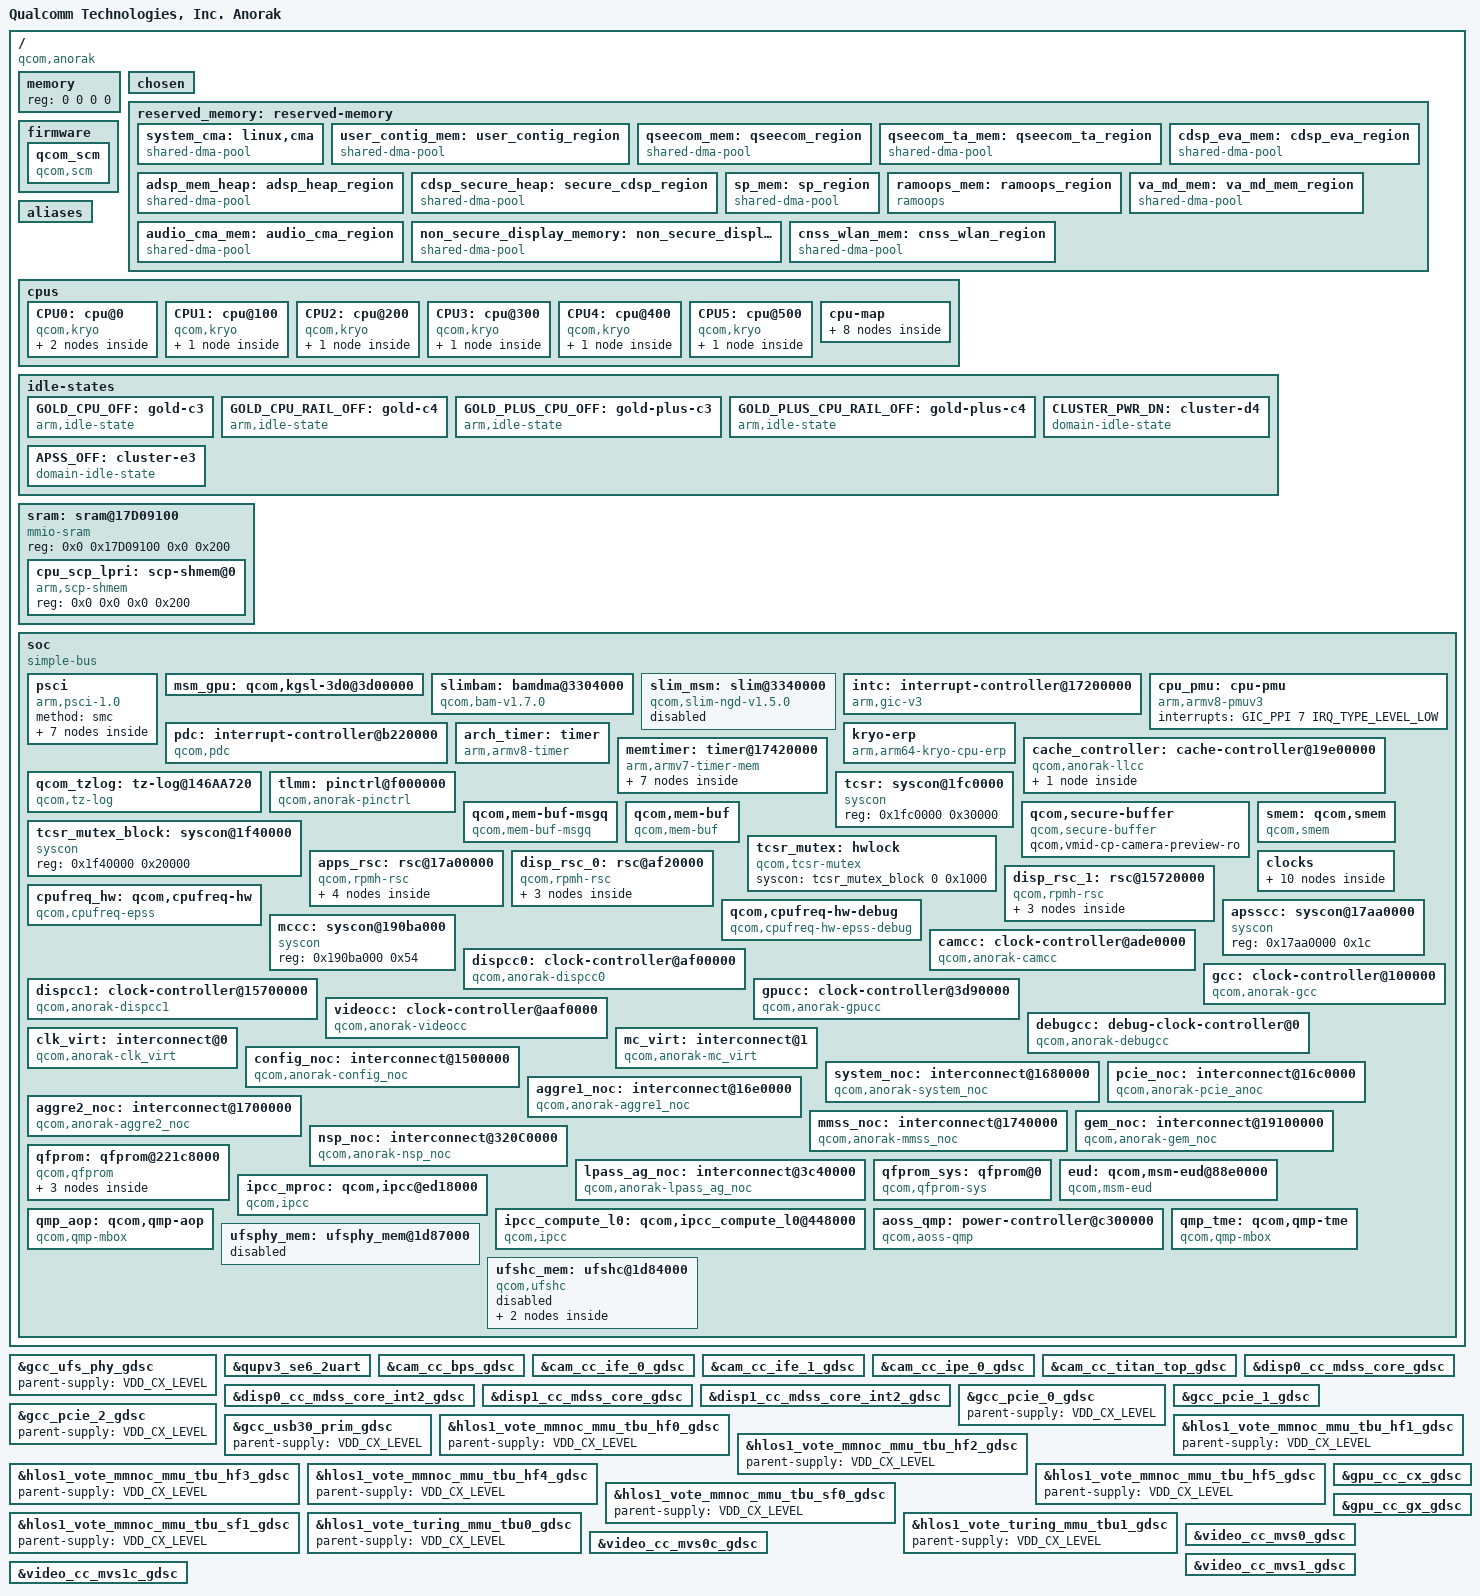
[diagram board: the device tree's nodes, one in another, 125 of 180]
#include <dt-bindings/clock/qcom,rpmh.h>
#include <dt-bindings/clock/qcom,camcc-anorak.h>
#include <dt-bindings/clock/qcom,dispcc-anorak.h>
#include <dt-bindings/clock/qcom,gcc-anorak.h>
#include <dt-bindings/clock/qcom,gpucc-anorak.h>
#include <dt-bindings/clock/qcom,videocc-anorak.h>
#include <dt-bindings/interrupt-controller/arm-gic.h>
#include <dt-bindings/soc/qcom,rpmh-rsc.h>
#include <dt-bindings/regulator/qcom,rpmh-regulator-levels.h>
#include <dt-bindings/interconnect/qcom,icc.h>
#include <dt-bindings/interconnect/qcom,anorak.h>
#include <dt-bindings/power/qcom-aoss-qmp.h>
#include <dt-bindings/clock/qcom,aop-qmp.h>
#include <dt-bindings/soc/qcom,ipcc.h>
#include <dt-bindings/gpio/gpio.h>

/ {
	model = "Qualcomm Technologies, Inc. Anorak";
	compatible = "qcom,anorak";
	qcom,msm-id = <549 0x10000>;
	interrupt-parent = <&intc>;

	#address-cells = <2>;
	#size-cells = <2>;
	memory { device_type = "memory"; reg = <0 0 0 0>; };

	chosen: chosen { bootargs = "console=ttyMSM0,115200n8 loglevel=6 log_buf_len=256K kernel.panic_on_rcu_stall=1 loop.max_part=7 pcie_ports=compat service_locator.enable=1 msm_rtb.filter=0x237 allow_mismatched_32bit_el0 kasan=off rcupdate.rcu_expedited=1 ftrace_dump_on_oops kpti=off rcu_nocbs=0-5 swiotlb=noforce cgroup.memory=nokmem,nosocket can.stats_timer=0 disable_dma32=on cpufreq.default_governor=performance ufs_qcom.crash_on_ber=n"; };

	reserved_memory: reserved-memory { };

	firmware: firmware { };

	aliases: aliases {
			serial0 = &qupv3_se6_2uart;
			ufshc1 = &ufshc_mem; /* Embedded UFS Slot */
			hsuart0 = &qupv3_se5_4uart;
	};

	cpus {
		#address-cells = <2>;
		#size-cells = <0>;

		CPU0: cpu@0 {
			device_type = "cpu";
			compatible = "qcom,kryo";
			reg = <0x0 0x0>;
			cpu-idle-states = <&GOLD_CPU_OFF &GOLD_CPU_RAIL_OFF>;
			power-domains = <&CPU_PD0>;
			power-domain-names = "psci";
			enable-method = "psci";
			next-level-cache = <&L2_0>;
			capacity-dmips-mhz = <1024>;
			dynamic-power-coefficient = <100>;
			#cooling-cells = <2>;
			qcom,freq-domain = <&cpufreq_hw 0>;
			L2_0: l2-cache {
			      compatible = "arm,arch-cache";
			      cache-level = <2>;
			      next-level-cache = <&L3_0>;

				L3_0: l3-cache {
					compatible = "arm,arch-cache";
					cache-level = <3>;
				};
			};
		};

		CPU1: cpu@100 {
			device_type = "cpu";
			compatible = "qcom,kryo";
			reg = <0x0 0x100>;
			enable-method = "psci";
			cpu-idle-states = <&GOLD_CPU_OFF &GOLD_CPU_RAIL_OFF>;
			power-domains = <&CPU_PD1>;
			power-domain-names = "psci";
			next-level-cache = <&L2_1>;
			capacity-dmips-mhz = <1024>;
			dynamic-power-coefficient = <100>;
			#cooling-cells = <2>;
			qcom,freq-domain = <&cpufreq_hw 0>;
			L2_1: l2-cache {
			      compatible = "arm,arch-cache";
			      cache-level = <2>;
			      next-level-cache = <&L3_0>;
			};

		};

		CPU2: cpu@200 {
			device_type = "cpu";
			compatible = "qcom,kryo";
			reg = <0x0 0x200>;
			enable-method = "psci";
			cpu-idle-states = <&GOLD_PLUS_CPU_OFF &GOLD_PLUS_CPU_RAIL_OFF>;
			power-domains = <&CPU_PD2>;
			power-domain-names = "psci";
			next-level-cache = <&L2_2>;
			capacity-dmips-mhz = <1075>;
			dynamic-power-coefficient = <109>;
			#cooling-cells = <2>;
			qcom,freq-domain = <&cpufreq_hw 1>;
			L2_2: l2-cache {
			      compatible = "arm,arch-cache";
			      cache-level = <2>;
			      next-level-cache = <&L3_0>;
			};
		};

		CPU3: cpu@300 {
			device_type = "cpu";
			compatible = "qcom,kryo";
			reg = <0x0 0x300>;
			enable-method = "psci";
			cpu-idle-states = <&GOLD_PLUS_CPU_OFF &GOLD_PLUS_CPU_RAIL_OFF>;
			power-domains = <&CPU_PD3>;
			power-domain-names = "psci";
			next-level-cache = <&L2_3>;
			capacity-dmips-mhz = <1075>;
			dynamic-power-coefficient = <109>;
			#cooling-cells = <2>;
			qcom,freq-domain = <&cpufreq_hw 1>;
			L2_3: l2-cache {
			      compatible = "arm,arch-cache";
			      cache-level = <2>;
			      next-level-cache = <&L3_0>;
			};

		};

		CPU4: cpu@400 {
			device_type = "cpu";
			compatible = "qcom,kryo";
			reg = <0x0 0x400>;
			enable-method = "psci";
			cpu-idle-states = <&GOLD_PLUS_CPU_OFF &GOLD_PLUS_CPU_RAIL_OFF>;
			power-domains = <&CPU_PD4>;
			power-domain-names = "psci";
			next-level-cache = <&L2_4>;
			capacity-dmips-mhz = <1075>;
			dynamic-power-coefficient = <109>;
			#cooling-cells = <2>;
			qcom,freq-domain = <&cpufreq_hw 1>;
			L2_4: l2-cache {
				compatible = "arm,arch-cache";
				cache-level = <2>;
				next-level-cache = <&L3_0>;
			};
		};

		CPU5: cpu@500 {
			device_type = "cpu";
			compatible = "qcom,kryo";
			reg = <0x0 0x500>;
			enable-method = "psci";
			cpu-idle-states = <&GOLD_PLUS_CPU_OFF &GOLD_PLUS_CPU_RAIL_OFF>;
			power-domains = <&CPU_PD5>;
			power-domain-names = "psci";
			next-level-cache = <&L2_5>;
			capacity-dmips-mhz = <1075>;
			dynamic-power-coefficient = <109>;
			#cooling-cells = <2>;
			qcom,freq-domain = <&cpufreq_hw 1>;
			L2_5: l2-cache {
				compatible = "arm,arch-cache";
				cache-level = <2>;
				next-level-cache = <&L3_0>;
			};
		};

		cpu-map {
			cluster0 {
				core0 {
					cpu = <&CPU0>;
				};

				core1 {
					cpu = <&CPU1>;
				};
			};

			cluster1 {
				core0 {
					cpu = <&CPU2>;
				};

				core1 {
					cpu = <&CPU3>;
				};

				core2 {
					cpu = <&CPU4>;
				};

				core3 {
					cpu = <&CPU5>;
				};
			};
		};
	};

	idle-states {
		GOLD_CPU_OFF: gold-c3 {  /* C3 */
			compatible = "arm,idle-state";
			idle-state-name = "pc";
			entry-latency-us = <400>;
			exit-latency-us = <1400>;
			min-residency-us = <2207>;
			arm,psci-suspend-param = <0x40000003>;
			local-timer-stop;
		};

		GOLD_CPU_RAIL_OFF: gold-c4 {  /* C4 */
			compatible = "arm,idle-state";
			idle-state-name = "rail-pc";
			entry-latency-us = <600>;
			exit-latency-us = <1300>;
			min-residency-us = <8136>;
			arm,psci-suspend-param = <0x40000004>;
			local-timer-stop;
		};

		GOLD_PLUS_CPU_OFF: gold-plus-c3 {  /* C3 */
			compatible = "arm,idle-state";
			idle-state-name = "pc";
			entry-latency-us = <300>;
			exit-latency-us = <1450>;
			min-residency-us = <3230>;
			arm,psci-suspend-param = <0x40000003>;
			local-timer-stop;
		};

		GOLD_PLUS_CPU_RAIL_OFF: gold-plus-c4 {  /* C4 */
			compatible = "arm,idle-state";
			idle-state-name = "rail-pc";
			entry-latency-us = <500>;
			exit-latency-us = <1350>;
			min-residency-us = <7480>;
			arm,psci-suspend-param = <0x40000004>;
			local-timer-stop;
		};

		CLUSTER_PWR_DN: cluster-d4 { /* D4 */
			compatible = "domain-idle-state";
			idle-state-name = "l3-off";
			entry-latency-us = <1050>;
			exit-latency-us = <2500>;
			min-residency-us = <9309>;
			arm,psci-suspend-param = <0x41000044>;
		};

		APSS_OFF: cluster-e3 { /* E3 */
			compatible = "domain-idle-state";
			idle-state-name = "llcc-off";
			entry-latency-us = <2700>;
			exit-latency-us = <3500>;
			min-residency-us = <13959>;
			arm,psci-suspend-param = <0x4100c344>;
		};
	};

	sram: sram@17D09100 {
		#address-cells = <2>;
		#size-cells = <2>;
		compatible = "mmio-sram";
		reg = <0x0 0x17D09100 0x0 0x200>;
		ranges = <0x0 0x0 0x0 0x17D09100 0x0 0x200>;

		cpu_scp_lpri: scp-shmem@0 {
			compatible = "arm,scp-shmem";
			reg = <0x0 0x0 0x0 0x200>;
		};
	};

	soc: soc { };
};

#include "anorak-reserved-memory.dtsi"

&reserved_memory {
	#address-cells = <2>;
	#size-cells = <2>;
	ranges;

	/* global autoconfigured region for contiguous allocations */
	system_cma: linux,cma {
		compatible = "shared-dma-pool";
		alloc-ranges = <0x0 0x00000000 0x0 0xffffffff>;
		reusable;
		alignment = <0x0 0x400000>;
		size = <0x0 0x2000000>;
		linux,cma-default;
	};

	user_contig_mem: user_contig_region {
		compatible = "shared-dma-pool";
		alloc-ranges = <0x0 0x00000000 0x0 0xffffffff>;
		reusable;
		alignment = <0x0 0x400000>;
		size = <0x0 0x1000000>;
	};

	qseecom_mem: qseecom_region {
		compatible = "shared-dma-pool";
		alloc-ranges = <0x0 0x00000000 0x0 0xffffffff>;
		reusable;
		alignment = <0x0 0x400000>;
		size = <0x0 0x1400000>;
	};

	qseecom_ta_mem: qseecom_ta_region {
		compatible = "shared-dma-pool";
		alloc-ranges = <0x0 0x00000000 0x0 0xffffffff>;
		reusable;
		alignment = <0x0 0x400000>;
		size = <0x0 0x1000000>;
	};

	cdsp_eva_mem: cdsp_eva_region {
		compatible = "shared-dma-pool";
		alloc-ranges = <0x0 0x00000000 0x0 0xffffffff>;
		reusable;
		alignment = <0x0 0x400000>;
		size = <0x0 0x400000>;
	};

	adsp_mem_heap: adsp_heap_region {
		compatible = "shared-dma-pool";
		alloc-ranges = <0x0 0x00000000 0x0 0xffffffff>;
		reusable;
		alignment = <0x0 0x400000>;
		size = <0x0 0xC00000>;
	};

	cdsp_secure_heap: secure_cdsp_region { /* Secure DSP */
		compatible = "shared-dma-pool";
		alloc-ranges = <0x0 0x00000000 0x0 0xffffffff>;
		reusable;
		alignment = <0x0 0x400000>;
		size = <0x0 0x2800000>;
	};

	sp_mem: sp_region {  /* SPSS-HLOS ION shared mem */
		compatible = "shared-dma-pool";
		alloc-ranges = <0x0 0x00000000 0x0 0xffffffff>;
		reusable;
		alignment = <0x0 0x400000>;
		size = <0x0 0x1000000>;
	};

	ramoops_mem: ramoops_region {
		compatible = "ramoops";
		alloc-ranges = <0x0 0x00000000 0xffffffff 0xffffffff>;
		size = <0x0 0x200000>;
		pmsg-size = <0x200000>;
		mem-type = <2>;
	};

	va_md_mem: va_md_mem_region {
		compatible = "shared-dma-pool";
		alloc-ranges = <0x1 0x00000000 0xfffffffe 0xffffffff>;
		reusable;
		size = <0 0x1000000>;
	};

	audio_cma_mem: audio_cma_region {
	compatible = "shared-dma-pool";
	alloc-ranges = <0x0 0x00000000 0x0 0xffffffff>;
	reusable;
	alignment = <0x0 0x400000>;
	size = <0x0 0x1000000>;
	};

	non_secure_display_memory: non_secure_display_region {
		compatible = "shared-dma-pool";
		reusable;
		alloc-ranges = <0x0 0x00000000 0x0 0xffffffff>;
		size = <0x0 0xa400000>;
		alignment = <0x0 0x400000>;
	};

	cnss_wlan_mem: cnss_wlan_region {
		compatible = "shared-dma-pool";
		alloc-ranges = <0x0 0x00000000 0x0 0xffffffff>;
		reusable;
		alignment = <0x0 0x400000>;
		size = <0x0 0x2000000>;
	};
};

&firmware {
	qcom_scm {
		compatible = "qcom,scm";
		qcom,dload-mode = <&tcsr 0x13000>;
		qcom,no-multi-smc-support;
	};
};

&soc {
	#address-cells = <1>;
	#size-cells = <1>;
	ranges = <0 0 0 0xffffffff>;
	compatible = "simple-bus";

	psci {
		compatible = "arm,psci-1.0";
		method = "smc";

		CPU_PD0: cpu-pd0 {
			#power-domain-cells = <0>;
			power-domains = <&CLUSTER_PD>;
		};

		CPU_PD1: cpu-pd1 {
			#power-domain-cells = <0>;
			power-domains = <&CLUSTER_PD>;
		};

		CPU_PD2: cpu-pd2 {
			#power-domain-cells = <0>;
			power-domains = <&CLUSTER_PD>;
		};

		CPU_PD3: cpu-pd3 {
			#power-domain-cells = <0>;
			power-domains = <&CLUSTER_PD>;
		};

		CPU_PD4: cpu-pd4 {
			#power-domain-cells = <0>;
			power-domains = <&CLUSTER_PD>;
		};

		CPU_PD5: cpu-pd5 {
			#power-domain-cells = <0>;
			power-domains = <&CLUSTER_PD>;
		};

		CLUSTER_PD: cluster-pd {
			#power-domain-cells = <0>;
			domain-idle-states = <&CLUSTER_PWR_DN &APSS_OFF>;
		};
	};

	msm_gpu: qcom,kgsl-3d0@3d00000 { };

	slimbam: bamdma@3304000 {
		compatible = "qcom,bam-v1.7.0";
		qcom,controlled-remotely;
		reg = <0x3304000 0x20000>, <0x326b000 0x1000>;
		reg-names = "bam", "bam_remote_mem";
		num-channels  = <31>;
		interrupts = <0 164 IRQ_TYPE_LEVEL_HIGH>;
		#dma-cells = <1>;
		qcom,ee = <1>;
		qcom,num-ees = <2>;
	};

	slim_msm: slim@3340000 {
		compatible = "qcom,slim-ngd-v1.5.0";
		reg = <0x3340000 0x2C000>, <0x326a000 0x1000>;
		reg-names = "ctrl", "slimbus_remote_mem";
		interrupts = <0 163 IRQ_TYPE_LEVEL_HIGH>;
		dmas = <&slimbam 3>, <&slimbam 4>;
		dma-names = "rx", "tx";
		#address-cells = <1>;
		#size-cells = <0>;
		status = "disabled";
	};

	intc: interrupt-controller@17200000 {
		compatible = "arm,gic-v3";
		#interrupt-cells = <3>;
		interrupt-controller;
		#redistributor-regions = <1>;
		redistributor-stride = <0x0 0x20000>;
		reg = <0x17200000 0x10000>,	/* GICD */
		      <0x17260000 0x100000>;	/* GICR * 8 */
		interrupts = <GIC_PPI 9 IRQ_TYPE_LEVEL_LOW>;
	};

	cpu_pmu: cpu-pmu {
		compatible = "arm,armv8-pmuv3";
		interrupts = <GIC_PPI 7 IRQ_TYPE_LEVEL_LOW>;
	};

	pdc: interrupt-controller@b220000 {
		compatible = "qcom,pdc";
		reg = <0xb220000 0x30000>, <0x174000f0 0x64>;
		reg-names = "pdc-interrupt-base", "apss-shared-spi-cfg";
		qcom,pdc-ranges = <0 480 94>, <94 609 31>, <125 63 1>,
					<126 716 12>;
		#interrupt-cells = <2>;
		interrupt-parent = <&intc>;
		interrupt-controller;
	};


	arch_timer: timer {
		compatible = "arm,armv8-timer";
		interrupts = <GIC_PPI 13 (GIC_CPU_MASK_SIMPLE(8) | IRQ_TYPE_LEVEL_LOW)>,
			     <GIC_PPI 14 (GIC_CPU_MASK_SIMPLE(8) | IRQ_TYPE_LEVEL_LOW)>,
			     <GIC_PPI 11 (GIC_CPU_MASK_SIMPLE(8) | IRQ_TYPE_LEVEL_LOW)>,
			     <GIC_PPI 12 (GIC_CPU_MASK_SIMPLE(8) | IRQ_TYPE_LEVEL_LOW)>;
		clock-frequency = <19200000>;
	};

	kryo-erp {
		compatible = "arm,arm64-kryo-cpu-erp";
		interrupts = <GIC_PPI 0 IRQ_TYPE_LEVEL_HIGH>,
				<GIC_SPI 35 IRQ_TYPE_LEVEL_HIGH>;
		interrupt-names = "l1-l2-faultirq", "l3-scu-faultirq";
	};

	memtimer: timer@17420000 {
		#address-cells = <1>;
		#size-cells = <1>;
		ranges;
		compatible = "arm,armv7-timer-mem";
		reg = <0x17420000 0x1000>;
		clock-frequency = <19200000>;

		frame@17421000 {
			frame-number = <0>;
			interrupts = <GIC_SPI 8 IRQ_TYPE_LEVEL_HIGH>,
				     <GIC_SPI 6 IRQ_TYPE_LEVEL_HIGH>;
			reg = <0x17421000 0x1000>,
			      <0x17422000 0x1000>;
		};

		frame@17423000 {
			frame-number = <1>;
			interrupts = <GIC_SPI 9 IRQ_TYPE_LEVEL_HIGH>;
			reg = <0x17423000 0x1000>;
			status = "disabled";
		};

		frame@17425000 {
			frame-number = <2>;
			interrupts = <GIC_SPI 10 IRQ_TYPE_LEVEL_HIGH>;
			reg = <0x17425000 0x1000>;
			status = "disabled";
		};

		frame@17427000 {
			frame-number = <3>;
			interrupts = <GIC_SPI 11 IRQ_TYPE_LEVEL_HIGH>;
			reg = <0x17427000 0x1000>;
			status = "disabled";
		};

		frame@17429000 {
			frame-number = <4>;
			interrupts = <GIC_SPI 12 IRQ_TYPE_LEVEL_HIGH>;
			reg = <0x17429000 0x1000>;
			status = "disabled";
		};

		frame@1742b000 {
			frame-number = <5>;
			interrupts = <GIC_SPI 13 IRQ_TYPE_LEVEL_HIGH>;
			reg = <0x1742b000 0x1000>;
			status = "disabled";
		};

		frame@1742d000 {
			frame-number = <6>;
			interrupts = <GIC_SPI 14 IRQ_TYPE_LEVEL_HIGH>;
			reg = <0x1742d000 0x1000>;
			status = "disabled";
		};
	};

	cache_controller: cache-controller@19e00000 {
		compatible = "qcom,anorak-llcc", "qcom,llcc-v41";
		reg = <0x19e00000 0x800000>, <0x1a600000 0x200000>;
		reg-names = "llcc_base", "llcc_broadcast_base";
		interrupts = <GIC_SPI 266 IRQ_TYPE_LEVEL_HIGH>;
		cap-based-alloc-and-pwr-collapse;

		llcc-perfmon {
			compatible = "qcom,llcc-perfmon";
			clocks = <&aoss_qmp QDSS_CLK>;
			clock-names = "qdss_clk";
		};
	};

	qcom_tzlog: tz-log@146AA720 {
		compatible = "qcom,tz-log";
		reg = <0x146AA720 0x3000>;
		qcom,hyplog-enabled;
		hyplog-address-offset = <0x410>;
		hyplog-size-offset = <0x414>;
		tmecrashdump-address-offset = <0x81CA0000>;
	};

	tlmm: pinctrl@f000000 {
		compatible = "qcom,anorak-pinctrl";
		reg = <0xf000000 0x1000000>;
		interrupts = <GIC_SPI 208 IRQ_TYPE_LEVEL_HIGH>;
		gpio-controller;
		#gpio-cells = <2>;
		interrupt-controller;
		#interrupt-cells = <2>;
	};

	tcsr: syscon@1fc0000 {
		compatible = "syscon";
		reg = <0x1fc0000 0x30000>;
	};

	qcom,mem-buf-msgq {
		compatible = "qcom,mem-buf-msgq";
	};

	qcom,mem-buf {
		compatible = "qcom,mem-buf";
		qcom,mem-buf-capabilities = "supplier";
		qcom,vmid = <3>;
	};

	qcom,secure-buffer {
		compatible = "qcom,secure-buffer";
		qcom,vmid-cp-camera-preview-ro;
	};

	tcsr_mutex_block: syscon@1f40000 {
		compatible = "syscon";
		reg = <0x1f40000 0x20000>;
	};

	tcsr_mutex: hwlock {
		compatible = "qcom,tcsr-mutex";
		syscon = <&tcsr_mutex_block 0 0x1000>;
		#hwlock-cells = <1>;
	};

	smem: qcom,smem {
		compatible = "qcom,smem";
		memory-region = <&smem_mem>;
		hwlocks = <&tcsr_mutex 3>;
	};

	apps_rsc: rsc@17a00000 {
		label = "apps_rsc";
		compatible = "qcom,rpmh-rsc";
		reg = <0x17a00000 0x10000>,
		      <0x17a10000 0x10000>,
		      <0x17a20000 0x10000>;
		reg-names = "drv-0", "drv-1", "drv-2";
		qcom,drv-count = <3>;
		interrupts = <GIC_SPI 3 IRQ_TYPE_LEVEL_HIGH>,
			     <GIC_SPI 4 IRQ_TYPE_LEVEL_HIGH>,
			     <GIC_SPI 5 IRQ_TYPE_LEVEL_HIGH>;
		power-domains = <&CLUSTER_PD>;

		apps_rsc_drv2: drv@2 {
			qcom,drv-id = <2>;
			qcom,tcs-offset = <0xd00>;
			channel@0 {
				qcom,tcs-config = <ACTIVE_TCS    3>,
						  <SLEEP_TCS     2>,
						  <WAKE_TCS      2>,
						  <FAST_PATH_TCS 1>,
						  <CONTROL_TCS   0>;
			};

			rpmhcc: qcom,rpmhclk {
				compatible = "qcom,anorak-rpmh-clk";
				#clock-cells = <1>;
			};

			apps_bcm_voter: bcm_voter {
				compatible = "qcom,bcm-voter";
			};

		};
	};

	disp_rsc_0: rsc@af20000 {
		label = "disp_rsc_0";
		compatible = "qcom,rpmh-rsc";
		reg = <0xaf20000 0x10000>;
		reg-names = "drv-0";
		qcom,drv-count = <1>;
		interrupts = <GIC_SPI 129 IRQ_TYPE_LEVEL_HIGH>;

		disp_rsc_0_drv0: drv@0 {
			qcom,drv-id = <0>;
			qcom,tcs-offset = <0x1c00>;
			channel@0 {
				qcom,tcs-config = <ACTIVE_TCS    0>,
						  <SLEEP_TCS     1>,
						  <WAKE_TCS      1>,
						  <CONTROL_TCS   0>,
						  <FAST_PATH_TCS 0>;
			};

			disp0_bcm_voter: bcm_voter {
				compatible = "qcom,bcm-voter";
				qcom,tcs-wait = <QCOM_ICC_TAG_AMC>;
			};
		};
	};

	disp_rsc_1: rsc@15720000 {
		label = "disp_rsc_1";
		compatible = "qcom,rpmh-rsc";
		reg = <0x15720000 0x10000>;
		reg-names = "drv-0";
		qcom,drv-count = <1>;
		interrupts = <GIC_SPI 218 IRQ_TYPE_LEVEL_HIGH>;

		disp_rsc_1_drv0: drv@0 {
			qcom,drv-id = <0>;
			qcom,tcs-offset = <0x1c00>;
			channel@0 {
				qcom,tcs-config = <ACTIVE_TCS    0>,
						  <SLEEP_TCS     1>,
						  <WAKE_TCS      1>,
						  <CONTROL_TCS   0>,
						  <FAST_PATH_TCS 0>;
			};

			disp1_bcm_voter: bcm_voter {
				compatible = "qcom,bcm-voter";
				qcom,tcs-wait = <QCOM_ICC_TAG_AMC>;
			};
		};
	};

	clocks {
		xo_board: xo_board {
			compatible = "fixed-clock";
			clock-frequency = <76800000>;
			clock-output-names = "xo_board";
			#clock-cells = <0>;
		};

		sleep_clk: sleep_clk {
			compatible = "fixed-clock";
			clock-frequency = <32000>;
			clock-output-names = "sleep_clk";
			#clock-cells = <0>;
		};

		pcie_0_pipe_clk: pcie_0_pipe_clk {
			compatible = "fixed-clock";
			clock-frequency = <1000>;
			clock-output-names = "pcie_0_pipe_clk";
			#clock-cells = <0>;
		};

		pcie_1_pipe_clk: pcie_1_pipe_clk {
			compatible = "fixed-clock";
			clock-frequency = <1000>;
			clock-output-names = "pcie_1_pipe_clk";
			#clock-cells = <0>;
		};

		pcie_2_phy_aux_clk: pcie_2_phy_aux_clk {
			compatible = "fixed-clock";
			clock-frequency = <1000>;
			clock-output-names = "pcie_2_phy_aux_clk";
			#clock-cells = <0>;
		};

		pcie_2_pipe_clk: pcie_2_pipe_clk {
			compatible = "fixed-clock";
			clock-frequency = <1000>;
			clock-output-names = "pcie_2_pipe_clk";
			#clock-cells = <0>;
		};

		ufs_phy_rx_symbol_0_clk: ufs_phy_rx_symbol_0_clk {
			compatible = "fixed-clock";
			clock-frequency = <1000>;
			clock-output-names = "ufs_phy_rx_symbol_0_clk";
			#clock-cells = <0>;
		};

		ufs_phy_rx_symbol_1_clk: ufs_phy_rx_symbol_1_clk {
			compatible = "fixed-clock";
			clock-frequency = <1000>;
			clock-output-names = "ufs_phy_rx_symbol_1_clk";
			#clock-cells = <0>;
		};

		ufs_phy_tx_symbol_0_clk: ufs_phy_tx_symbol_0_clk {
			compatible = "fixed-clock";
			clock-frequency = <1000>;
			clock-output-names = "ufs_phy_tx_symbol_0_clk";
			#clock-cells = <0>;
		};

		usb3_phy_wrapper_gcc_usb30_pipe_clk: usb3_phy_wrapper_gcc_usb30_pipe_clk {
			compatible = "fixed-clock";
			clock-frequency = <1000>;
			clock-output-names = "usb3_phy_wrapper_gcc_usb30_pipe_clk";
			#clock-cells = <0>;
		};
	};

	cpufreq_hw: qcom,cpufreq-hw {
		compatible =  "qcom,cpufreq-epss";
		reg = <0x17d91000 0x1000>,
		      <0x17d92000 0x1000>;
		reg-names = "freq-domain0", "freq-domain1";
		clocks = <&rpmhcc RPMH_CXO_CLK>, <&gcc GCC_GPLL0>;
		clock-names = "xo", "alternate";
		interrupts = <GIC_SPI 30 IRQ_TYPE_LEVEL_HIGH>,
			     <GIC_SPI 31 IRQ_TYPE_LEVEL_HIGH>;
		interrupt-names = "dcvsh0_int", "dcvsh1_int";
		#freq-domain-cells = <1>;
	};

	qcom,cpufreq-hw-debug {
		compatible = "qcom,cpufreq-hw-epss-debug";
		qcom,freq-hw-domain = <&cpufreq_hw 0>, <&cpufreq_hw 1>;
	};

	apsscc: syscon@17aa0000 {
		compatible = "syscon";
		reg = <0x17aa0000 0x1c>;
	};

	mccc: syscon@190ba000 {
		compatible = "syscon";
		reg = <0x190ba000 0x54>;
	};

	camcc: clock-controller@ade0000 {
		compatible = "qcom,anorak-camcc", "syscon";
		reg = <0xade0000 0x20000>;
		reg-name = "cc_base";
		vdd_mm-supply = <&VDD_MM_LEVEL>;
		vdd_mxa-supply = <&VDD_MXA_LEVEL>;
		vdd_mxc-supply = <&VDD_MXC_LEVEL>;
		clocks = <&rpmhcc RPMH_CXO_CLK>,
			<&sleep_clk>,
			<&gcc GCC_CAMERA_AHB_CLK>;
		clock-names = "bi_tcxo",
			"sleep_clk","iface";
		clock-output-names = "camcc_clocks";
		#clock-cells = <1>;
		#reset-cells = <1>;
	};

	dispcc0: clock-controller@af00000 {
		compatible = "qcom,anorak-dispcc0", "syscon";
		reg = <0xaf00000 0x20000>;
		reg-name = "cc_base";
		vdd_mm-supply = <&VDD_MM_LEVEL>;
		vdd_mxa-supply = <&VDD_MXA_LEVEL>;
		clocks = <&rpmhcc RPMH_CXO_CLK>,
			 <&rpmhcc RPMH_CXO_CLK_A>,
			 <&sleep_clk>,
			 <&gcc GCC_DISP_AHB_CLK>;
		clock-names = "bi_tcxo", "bi_tcxo_ao", "sleep_clk", "iface";
		#clock-cells = <1>;
		#reset-cells = <1>;
	};

	dispcc1: clock-controller@15700000 {
		compatible = "qcom,anorak-dispcc1", "syscon";
		reg = <0x15700000 0x20000>;
		reg-name = "cc_base";
		vdd_mm-supply = <&VDD_MM_LEVEL>;
		vdd_mxa-supply = <&VDD_MXA_LEVEL>;
		clocks = <&rpmhcc RPMH_CXO_CLK>,
			 <&rpmhcc RPMH_CXO_CLK_A>,
			 <&sleep_clk>,
			 <&gcc GCC_DISP1_AHB_CLK>;
		clock-names = "bi_tcxo", "bi_tcxo_ao", "sleep_clk", "iface";
		#clock-cells = <1>;
		#reset-cells = <1>;
	};

	gcc: clock-controller@100000 {
		compatible = "qcom,anorak-gcc", "syscon";
		reg = <0x100000 0x1f4200>;
		reg-name = "cc_base";
		vdd_cx-supply = <&VDD_CX_LEVEL>;
		vdd_mxa-supply = <&VDD_MXA_LEVEL>;
		clocks = <&rpmhcc RPMH_CXO_CLK>, <&sleep_clk>,
			<&pcie_0_pipe_clk>, <&pcie_1_pipe_clk>,
			<&pcie_2_phy_aux_clk>, <&pcie_2_pipe_clk>,
			<&ufs_phy_rx_symbol_0_clk>, <&ufs_phy_rx_symbol_1_clk>,
			<&ufs_phy_tx_symbol_0_clk>, <&usb3_phy_wrapper_gcc_usb30_pipe_clk>;
		clock-names = "bi_tcxo", "sleep_clk",
			"pcie_0_pipe_clk", "pcie_1_pipe_clk",
			"pcie_2_phy_aux_clk", "pcie_2_pipe_clk",
			"ufs_phy_rx_symbol_0_clk", "ufs_phy_rx_symbol_1_clk",
			"ufs_phy_tx_symbol_0_clk", "usb3_phy_wrapper_gcc_usb30_pipe_clk";
		#clock-cells = <1>;
		#reset-cells = <1>;
	};

	gpucc: clock-controller@3d90000 {
		compatible = "qcom,anorak-gpucc", "syscon";
		reg = <0x3d90000 0xa000>;
		reg-name = "cc_base";
		vdd_cx-supply = <&VDD_CX_LEVEL>;
		vdd_mxa-supply = <&VDD_MXA_LEVEL>;
		vdd_mxc-supply = <&VDD_MXC_LEVEL>;
		clocks = <&rpmhcc RPMH_CXO_CLK>,
			<&gcc GCC_GPU_GPLL0_CLK_SRC>,
			<&gcc GCC_GPU_GPLL0_DIV_CLK_SRC>;
		clock-names = "bi_tcxo", "gpll0_out_main",
			"gpll0_out_main_div";
		#clock-cells = <1>;
		#reset-cells = <1>;
	};

	videocc: clock-controller@aaf0000 {
		compatible = "qcom,anorak-videocc", "syscon";
		reg = <0xaaf0000 0x10000>;
		reg-name = "cc_base";
		vdd_mm-supply = <&VDD_MM_LEVEL>;
		vdd_mxc-supply = <&VDD_MXC_LEVEL>;
		clocks = <&rpmhcc RPMH_CXO_CLK>,
			 <&sleep_clk>,
			 <&gcc GCC_VIDEO_AHB_CLK>;
		clock-names = "bi_tcxo",
			      "sleep_clk",
			      "iface";
		#clock-cells = <1>;
		#reset-cells = <1>;
	};

	debugcc: debug-clock-controller@0 {
		compatible = "qcom,anorak-debugcc";
		qcom,gcc = <&gcc>;
		qcom,videocc = <&videocc>;
		qcom,camcc = <&camcc>;
		qcom,gpucc = <&gpucc>;
		qcom,dispcc0 = <&dispcc0>;
		qcom,dispcc1 = <&dispcc1>;
		qcom,apsscc = <&apsscc>;
		qcom,mccc = <&mccc>;
		clocks = <&rpmhcc RPMH_CXO_CLK>,
			<&gcc 0>,<&camcc 0>,
			<&dispcc0 0>,<&dispcc1 0>,
			<&gpucc 0>,<&videocc 0>;
		clock-names = "xo_clk_src",
			      "gcc","camcc",
			      "dispcc0","dispcc1",
			      "gpucc","videocc";
		#clock-cells = <1>;
	};

	clk_virt: interconnect@0 {
		compatible = "qcom,anorak-clk_virt";
		#interconnect-cells = <1>;
		qcom,bcm-voter-names = "hlos";
		qcom,bcm-voters = <&apps_bcm_voter>;
	};

	mc_virt: interconnect@1 {
		compatible = "qcom,anorak-mc_virt";
		#interconnect-cells = <1>;
		qcom,bcm-voter-names = "hlos", "disp0", "disp1";
		qcom,bcm-voters = <&apps_bcm_voter>, <&disp0_bcm_voter>, <&disp1_bcm_voter>;
	};

	config_noc: interconnect@1500000 {
		reg = <0x1500000 0x13080>;
		compatible = "qcom,anorak-config_noc";
		#interconnect-cells = <1>;
		qcom,bcm-voter-names = "hlos";
		qcom,bcm-voters = <&apps_bcm_voter>;
	};

	system_noc: interconnect@1680000 {
		reg = <0x01680000 0x13080>;
		compatible = "qcom,anorak-system_noc";
		#interconnect-cells = <1>;
		qcom,bcm-voter-names = "hlos";
		qcom,bcm-voters = <&apps_bcm_voter>;
	};

	pcie_noc: interconnect@16c0000 {
		reg = <0x16C0000 0xC080>;
		compatible = "qcom,anorak-pcie_anoc";
		#interconnect-cells = <1>;
		qcom,bcm-voter-names = "hlos";
		qcom,bcm-voters = <&apps_bcm_voter>;
		clocks = <&gcc GCC_AGGRE_NOC_PCIE_AXI_CLK>,
			<&gcc GCC_CFG_NOC_PCIE_ANOC_AHB_CLK>,
			<&gcc GCC_AGGRE_NOC_PCIE_SF_AXI_CLK>;
	};

	aggre1_noc: interconnect@16e0000 {
		reg = <0x16E0000 0x9080>;
		compatible = "qcom,anorak-aggre1_noc";
		#interconnect-cells = <1>;
		qcom,bcm-voter-names = "hlos";
		qcom,bcm-voters = <&apps_bcm_voter>;
		clocks = <&gcc GCC_AGGRE_USB3_PRIM_AXI_CLK>;
	};

	aggre2_noc: interconnect@1700000 {
		reg = <0x1700000 0x15080>;
		compatible = "qcom,anorak-aggre2_noc";
		#interconnect-cells = <1>;
		qcom,bcm-voter-names = "hlos";
		qcom,bcm-voters = <&apps_bcm_voter>;
		clocks = <&rpmhcc RPMH_IPA_CLK>;
	};

	mmss_noc: interconnect@1740000 {
		reg = <0x01740000 0x1C100>;
		compatible = "qcom,anorak-mmss_noc";
		#interconnect-cells = <1>;
		qcom,bcm-voter-names = "hlos", "disp0", "disp1";
		qcom,bcm-voters = <&apps_bcm_voter>, <&disp0_bcm_voter>, <&disp1_bcm_voter>;
	};

	gem_noc: interconnect@19100000 {
		reg = <0x19100000 0xA9080>;
		compatible = "qcom,anorak-gem_noc";
		#interconnect-cells = <1>;
		qcom,bcm-voter-names = "hlos", "disp0", "disp1";
		qcom,bcm-voters = <&apps_bcm_voter>, <&disp0_bcm_voter>, <&disp1_bcm_voter>;
	};

	nsp_noc: interconnect@320C0000 {
		reg = <0x320C0000 0x10000>;
		compatible = "qcom,anorak-nsp_noc";
		#interconnect-cells = <1>;
		qcom,bcm-voter-names = "hlos";
		qcom,bcm-voters = <&apps_bcm_voter>;
	};

	lpass_ag_noc: interconnect@3c40000 {
		reg = <0x3c40000 0x17200>;
		compatible = "qcom,anorak-lpass_ag_noc";
		#interconnect-cells = <1>;
		qcom,bcm-voter-names = "hlos";
		qcom,bcm-voters = <&apps_bcm_voter>;
	};

	qfprom: qfprom@221c8000 {
		compatible = "qcom,qfprom";
		reg = <0x221c8000 0x1000>;
		#address-cells = <1>;
		#size-cells = <1>;
		read-only;
		ranges;

		feat_conf10: feat_conf10@128 {
			reg = <0x128 0x4>;
		};

		feat_conf11: feat_conf11@12c {
			reg = <0x12c 0x4>;
		};

		gpu_speed_bin: gpu_speed_bin@119 {
			reg = <0x119 0x2>;
			bits = <7 8>;
		};
	};

	qfprom_sys: qfprom@0 {
		compatible = "qcom,qfprom-sys";

		nvmem-cells = <&feat_conf10>,
				<&feat_conf11>,
				<&gpu_speed_bin>;
		nvmem-cell-names = "feat_conf10",
				"feat_conf11",
				"gpu_speed_bin";
	};

	eud: qcom,msm-eud@88e0000 {
		compatible = "qcom,msm-eud";
		interrupt-names = "eud_irq";
		interrupt-parent = <&pdc>;
		interrupts = <11 IRQ_TYPE_LEVEL_HIGH>;
		reg = <0x088e0000 0x2000>,
			<0x088e2000 0x1000>;
		reg-names = "eud_base", "eud_mode_mgr2";
		qcom,secure-eud-en;
		status = "ok";
	};

	ipcc_mproc: qcom,ipcc@ed18000 {
		compatible = "qcom,ipcc";
		reg = <0x408000 0x1000>;
		interrupts = <GIC_SPI 229 IRQ_TYPE_LEVEL_HIGH>;
		interrupt-controller;
		#interrupt-cells = <3>;
		#mbox-cells = <2>;
	};

	ipcc_compute_l0: qcom,ipcc_compute_l0@448000 {
		compatible = "qcom,ipcc";
		reg = <0x448000 0x1000>;
		interrupts = <GIC_SPI 230 IRQ_TYPE_LEVEL_HIGH>;
		interrupt-controller;
		#interrupt-cells = <3>;
		#mbox-cells = <2>;
	};

	aoss_qmp: power-controller@c300000 {
		compatible = "qcom,aoss-qmp";
		reg = <0xc300000 0x400>;
		interrupt-parent = <&ipcc_mproc>;
		interrupts = <IPCC_CLIENT_AOP
				IPCC_MPROC_SIGNAL_GLINK_QMP
				IRQ_TYPE_EDGE_RISING>;
		mboxes = <&ipcc_mproc IPCC_CLIENT_AOP
		IPCC_MPROC_SIGNAL_GLINK_QMP>;

		#power-domain-cells = <1>;
		#clock-cells = <0>;
	};

	qmp_aop: qcom,qmp-aop {
		compatible = "qcom,qmp-mbox";
		qcom,qmp = <&aoss_qmp>;
		label = "aop";
		#mbox-cells = <1>;
	};

	qmp_tme: qcom,qmp-tme {
		compatible = "qcom,qmp-mbox";
		qcom,remote-pid = <14>;
		mboxes = <&ipcc_mproc IPCC_CLIENT_TME
				IPCC_MPROC_SIGNAL_GLINK_QMP>;
		mbox-names = "tme_qmp";
		interrupt-parent = <&ipcc_mproc>;
		interrupts = <IPCC_CLIENT_TME
				IPCC_MPROC_SIGNAL_GLINK_QMP
				IRQ_TYPE_EDGE_RISING>;

		label = "tme";
		qcom,early-boot;
		priority = <0>;
		mbox-desc-offset = <0x0>;
		#mbox-cells = <1>;
	};

	ufsphy_mem: ufsphy_mem@1d87000 {
		reg = <0x1d87000 0xe10>;
		reg-names = "phy_mem";
		#phy-cells = <0>;

		lanes-per-direction = <2>;
		clock-names = "ref_clk_src",
			"ref_aux_clk",
			"qref_clk",
			"rx_sym0_mux_clk", "rx_sym1_mux_clk", "tx_sym0_mux_clk",
			"rx_sym0_phy_clk", "rx_sym1_phy_clk", "tx_sym0_phy_clk";
		clocks = <&rpmhcc RPMH_CXO_CLK>,
			<&gcc GCC_UFS_PHY_PHY_AUX_CLK>,
			<&gcc GCC_UFS_0_CLKREF_EN>,
			<&gcc GCC_UFS_PHY_RX_SYMBOL_0_CLK_SRC>,
			<&gcc GCC_UFS_PHY_RX_SYMBOL_1_CLK_SRC>,
			<&gcc GCC_UFS_PHY_TX_SYMBOL_0_CLK_SRC>,
			<&ufs_phy_rx_symbol_0_clk>,
			<&ufs_phy_rx_symbol_1_clk>,
			<&ufs_phy_tx_symbol_0_clk>;

		resets = <&ufshc_mem 0>;
		status = "disabled";
	};

	ufshc_mem: ufshc@1d84000 {
		compatible = "qcom,ufshc";
		reg = <0x1d84000 0x3000>,
			<0x1d88000 0x8000>,
			<0x1d90000 0x9000>;
		reg-names = "ufs_mem", "ufs_ice", "ufs_ice_hwkm";
		interrupts = <GIC_SPI 265 IRQ_TYPE_LEVEL_HIGH>;
		phys = <&ufsphy_mem>;
		phy-names = "ufsphy";
		#reset-cells = <1>;

		lanes-per-direction = <2>;
		clock-names =
			"core_clk",
			"bus_aggr_clk",
			"iface_clk",
			"core_clk_unipro",
			"core_clk_ice",
			"ref_clk",
			"tx_lane0_sync_clk",
			"rx_lane0_sync_clk",
			"rx_lane1_sync_clk";
		clocks =
			<&gcc GCC_UFS_PHY_AXI_CLK>,
			<&gcc GCC_AGGRE_UFS_PHY_AXI_CLK>,
			<&gcc GCC_UFS_PHY_AHB_CLK>,
			<&gcc GCC_UFS_PHY_UNIPRO_CORE_CLK>,
			<&gcc GCC_UFS_PHY_ICE_CORE_CLK>,
			<&rpmhcc RPMH_CXO_CLK>,
			<&gcc GCC_UFS_PHY_TX_SYMBOL_0_CLK>,
			<&gcc GCC_UFS_PHY_RX_SYMBOL_0_CLK>,
			<&gcc GCC_UFS_PHY_RX_SYMBOL_1_CLK>;
		freq-table-hz =
			<75000000 300000000>,
			<0 0>,
			<0 0>,
			<75000000 300000000>,
			<75000000 300000000>,
			<0 0>,
			<0 0>,
			<0 0>,
			<0 0>;

		interconnects = <&aggre1_noc MASTER_UFS_MEM &mc_virt SLAVE_EBI1>,
		      <&gem_noc MASTER_APPSS_PROC &config_noc SLAVE_UFS_MEM_CFG>;
		interconnect-names = "ufs-ddr", "cpu-ufs";

		qcom,ufs-bus-bw,name = "ufshc_mem";
		qcom,ufs-bus-bw,num-cases = <26>;
		qcom,ufs-bus-bw,num-paths = <2>;
		qcom,ufs-bus-bw,vectors-KBps =
		/*
		 * During HS G3 UFS runs at nominal voltage corner, vote
		 * higher bandwidth to push other buses in the data path
		 * to run at nominal to achieve max throughput.
		 * 4GBps pushes BIMC to run at nominal.
		 * 200MBps pushes CNOC to run at nominal.
		 * Vote for half of this bandwidth for HS G3 1-lane.
		 * For max bandwidth, vote high enough to push the buses
		 * to run in turbo voltage corner.
		 */
		<0 0>, <0 0>,          /* No vote */
		<922 0>, <1000 0>,     /* PWM G1 */
		<1844 0>, <1000 0>,    /* PWM G2 */
		<3688 0>, <1000 0>,    /* PWM G3 */
		<7376 0>, <1000 0>,    /* PWM G4 */
		<1844 0>, <1000 0>,    /* PWM G1 L2 */
		<3688 0>, <1000 0>,    /* PWM G2 L2 */
		<7376 0>, <1000 0>,    /* PWM G3 L2 */
		<14752 0>, <1000 0>,   /* PWM G4 L2 */
		<127796 0>, <1000 0>,  /* HS G1 RA */
		<255591 0>, <1000 0>,  /* HS G2 RA */
		<1492582 0>, <102400 0>,  /* HS G3 RA */
		<2915200 0>, <204800 0>,  /* HS G4 RA */
		<255591 0>, <1000 0>,  /* HS G1 RA L2 */
		<511181 0>, <1000 0>,  /* HS G2 RA L2 */
		<1492582 0>, <204800 0>, /* HS G3 RA L2 */
		<2915200 0>, <409600 0>, /* HS G4 RA L2 */
		<149422 0>, <1000 0>,  /* HS G1 RB */
		<298189 0>, <1000 0>,  /* HS G2 RB */
		<1492582 0>, <102400 0>,  /* HS G3 RB */
		<2915200 0>, <204800 0>,  /* HS G4 RB */
		<298189 0>, <1000 0>,  /* HS G1 RB L2 */
		<596378 0>, <1000 0>,  /* HS G2 RB L2 */
		/* As UFS working in HS G3 RB L2 mode, aggregated
		 * bandwidth (AB) should take care of providing
		 * optimum throughput requested. However, as tested,
		 * in order to scale up CNOC clock, instantaneous
		 * bindwidth (IB) needs to be given a proper value too.
		 */
		<1492582 0>, <204800 409600>, /* HS G3 RB L2 KBPs */
		<2915200 0>, <409600 409600>, /* HS G4 RB L2 */
		<7643136 0>, <307200 0>; /* Max. bandwidth */

		qcom,bus-vector-names = "MIN",
		"PWM_G1_L1", "PWM_G2_L1", "PWM_G3_L1", "PWM_G4_L1",
		"PWM_G1_L2", "PWM_G2_L2", "PWM_G3_L2", "PWM_G4_L2",
		"HS_RA_G1_L1", "HS_RA_G2_L1", "HS_RA_G3_L1", "HS_RA_G4_L1",
		"HS_RA_G1_L2", "HS_RA_G2_L2", "HS_RA_G3_L2", "HS_RA_G4_L2",
		"HS_RB_G1_L1", "HS_RB_G2_L1", "HS_RB_G3_L1", "HS_RB_G4_L1",
		"HS_RB_G1_L2", "HS_RB_G2_L2", "HS_RB_G3_L2", "HS_RB_G4_L2",
		"MAX";

		iommus = <&apps_smmu 0x60 0x0>;
		qcom,iommu-dma = "fastmap";
		qcom,iommu-dma-addr-pool = <0x40000000 0x40000000>;
		qcom,iommu-geometry = <0x40000000 0x40000000>;
		dma-coherent;

		reset-gpios = <&tlmm 224 GPIO_ACTIVE_LOW>;
		resets = <&gcc GCC_UFS_PHY_BCR>;
		reset-names = "rst";

		status = "disabled";

		qos0 {
			mask = <0x3C>;
			vote = <44>;
			perf;
			cpu_freq_vote = <2>;
		};

		qos1 {
			mask = <0x03>;
			vote = <44>;
			cpu_freq_vote = <0>;
		};
	};
};

#include "anorak-gdsc.dtsi"
#include "anorak-qupv3.dtsi"

&gcc_ufs_phy_gdsc {
	parent-supply = <&VDD_CX_LEVEL>;
	status = "ok";
};

&qupv3_se6_2uart {
	status = "ok";
};

&cam_cc_bps_gdsc {
	clocks = <&gcc GCC_CAMERA_AHB_CLK>;
	clock-names = "ahb_clk";
	parent-supply = <&VDD_MM_MXC_VOTER_LEVEL>;
	reg = <0xadf0004 0x4>;
	status = "ok";
};

&cam_cc_ife_0_gdsc {
	clocks = <&gcc GCC_CAMERA_AHB_CLK>;
	clock-names = "ahb_clk";
	parent-supply = <&VDD_MM_MXC_VOTER_LEVEL>;
	reg = <0xadf1004 0x4>;
	status = "ok";
};

&cam_cc_ife_1_gdsc {
	clocks = <&gcc GCC_CAMERA_AHB_CLK>;
	clock-names = "ahb_clk";
	parent-supply = <&VDD_MM_MXC_VOTER_LEVEL>;
	reg = <0xadf2004 0x4>;
	status = "ok";
};

&cam_cc_ipe_0_gdsc {
	clocks = <&gcc GCC_CAMERA_AHB_CLK>;
	clock-names = "ahb_clk";
	parent-supply = <&VDD_MM_MXC_VOTER_LEVEL>;
	reg = <0xadf03b8 0x4>;
	status = "ok";
};

&cam_cc_titan_top_gdsc {
	clocks = <&gcc GCC_CAMERA_AHB_CLK>;
	clock-names = "ahb_clk";
	parent-supply = <&VDD_MM_MXC_VOTER_LEVEL>;
	reg = <0xadf4138 0x4>;
	status = "ok";
};

&disp0_cc_mdss_core_gdsc {
	parent-supply = <&VDD_MM_LEVEL>;
	clocks = <&gcc GCC_DISP_AHB_CLK>;
	clock-names = "ahb_clk";
	status = "ok";
};

&disp0_cc_mdss_core_int2_gdsc {
	parent-supply = <&VDD_MM_LEVEL>;
	clocks = <&gcc GCC_DISP_AHB_CLK>;
	clock-names = "ahb_clk";
	status = "ok";
};

&disp1_cc_mdss_core_gdsc {
	parent-supply = <&VDD_MM_LEVEL>;
	clocks = <&gcc GCC_DISP1_AHB_CLK>;
	clock-names = "ahb_clk";
	status = "ok";
};

&disp1_cc_mdss_core_int2_gdsc {
	parent-supply = <&VDD_MM_LEVEL>;
	clocks = <&gcc GCC_DISP1_AHB_CLK>;
	clock-names = "ahb_clk";
	status = "ok";
};

&gcc_pcie_0_gdsc {
	parent-supply = <&VDD_CX_LEVEL>;
	status="ok";
};

&gcc_pcie_1_gdsc {
	parent-supply = <&VDD_CX_LEVEL>;
	reg = <0x1ad004 0x4>;
	qcom,support-hw-trigger;
	status="ok";
};

&gcc_pcie_2_gdsc {
	parent-supply = <&VDD_CX_LEVEL>;
	status="ok";
};

&gcc_ufs_phy_gdsc {
	parent-supply = <&VDD_CX_LEVEL>;
	status = "ok";
};

&gcc_usb30_prim_gdsc {
	parent-supply = <&VDD_CX_LEVEL>;
	status = "ok";
};

&hlos1_vote_mmnoc_mmu_tbu_hf0_gdsc {
	parent-supply = <&VDD_CX_LEVEL>;
	status = "ok";
};

&hlos1_vote_mmnoc_mmu_tbu_hf1_gdsc {
	parent-supply = <&VDD_CX_LEVEL>;
	status = "ok";
};

&hlos1_vote_mmnoc_mmu_tbu_hf2_gdsc {
	parent-supply = <&VDD_CX_LEVEL>;
	status = "ok";
};

&hlos1_vote_mmnoc_mmu_tbu_hf3_gdsc {
	parent-supply = <&VDD_CX_LEVEL>;
	status = "ok";
};

&hlos1_vote_mmnoc_mmu_tbu_hf4_gdsc {
	parent-supply = <&VDD_CX_LEVEL>;
	status = "ok";
};

&hlos1_vote_mmnoc_mmu_tbu_hf5_gdsc {
	parent-supply = <&VDD_CX_LEVEL>;
	status = "ok";
};

&hlos1_vote_mmnoc_mmu_tbu_sf0_gdsc {
	parent-supply = <&VDD_CX_LEVEL>;
	status = "ok";
};

&hlos1_vote_mmnoc_mmu_tbu_sf1_gdsc {
	parent-supply = <&VDD_CX_LEVEL>;
	status = "ok";
};

&hlos1_vote_turing_mmu_tbu0_gdsc {
	parent-supply = <&VDD_CX_LEVEL>;
	status = "ok";
};

&hlos1_vote_turing_mmu_tbu1_gdsc {
	parent-supply = <&VDD_CX_LEVEL>;
	status = "ok";
};

&gpu_cc_cx_gdsc {
	clocks = <&gcc GCC_GPU_CFG_AHB_CLK>;
	clock-names = "ahb_clk";
	parent-supply = <&VDD_CX_LEVEL>;
	status = "ok";
};

&gpu_cc_gx_gdsc {
	clocks = <&gcc GCC_GPU_CFG_AHB_CLK>;
	clock-names = "ahb_clk";
	parent-supply = <&VDD_GFX_MXC_VOTER_LEVEL>;
	status = "ok";
};

&video_cc_mvs0_gdsc {
	reg = <0xaaf809c 0x4>;
	clocks = <&gcc GCC_VIDEO_AHB_CLK>;
	clock-names = "ahb_clk";
	parent-supply = <&VDD_MM_MXC_VOTER_LEVEL>;
	status = "ok";
};

&video_cc_mvs0c_gdsc {
	reg = <0xaaf804c 0x4>;
	clocks = <&gcc GCC_VIDEO_AHB_CLK>;
	clock-names = "ahb_clk";
	parent-supply = <&VDD_MM_MXC_VOTER_LEVEL>;
	status = "ok";
};

&video_cc_mvs1_gdsc {
	reg = <0xaaf80c0 0x4>;
	clocks = <&gcc GCC_VIDEO_AHB_CLK>;
	clock-names = "ahb_clk";
	parent-supply = <&VDD_MM_MXC_VOTER_LEVEL>;
	status = "ok";
};

&video_cc_mvs1c_gdsc {
	reg = <0xaaf8074 0x4>;
	clocks = <&gcc GCC_VIDEO_AHB_CLK>;
	clock-names = "ahb_clk";
	parent-supply = <&VDD_MM_MXC_VOTER_LEVEL>;
	status = "ok";
};

#include "anorak-regulators.dtsi"
#include "anorak-pinctrl.dtsi"
#include "msm-arm-smmu-anorak.dtsi"
#include "anorak-usb.dtsi"
